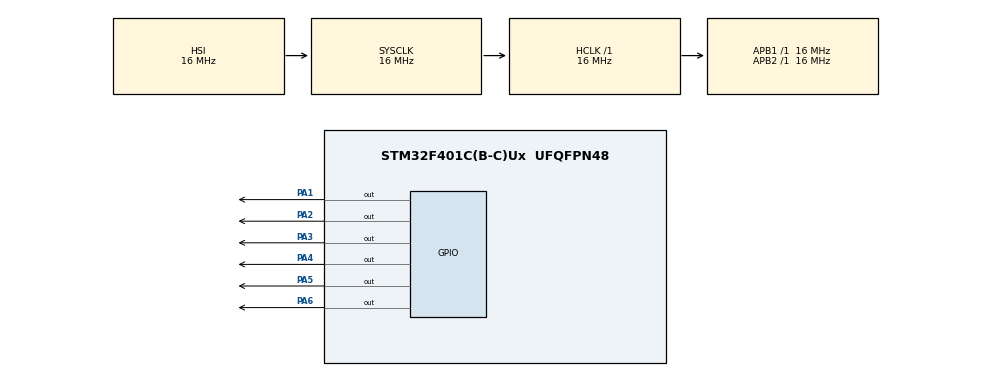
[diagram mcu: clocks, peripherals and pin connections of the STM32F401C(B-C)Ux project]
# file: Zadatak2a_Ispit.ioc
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FREERTOS.Tasks01=defaultTask,24,128,StartDefaultTask,Default,NULL,Dynamic,NULL,NULL
FREERTOS.configUSE_NEWLIB_REENTRANT=1
Mcu.Family=STM32F4
Mcu.Name=STM32F401C(B-C)Ux
Mcu.Package=UFQFPN48
NVIC.PriorityGroup=NVIC_PRIORITYGROUP_4
NVIC.TIM1_UP_TIM10_IRQn=true\:15\:0\:false\:false\:true\:false\:false\:true\:true
NVIC.TIM4_IRQn=true\:5\:0\:false\:false\:true\:true\:true\:true\:true
NVIC.TimeBase=TIM1_UP_TIM10_IRQn
NVIC.TimeBaseIP=TIM1
PA1.Signal=GPIO_Output
PA13.Mode=Serial_Wire
PA13.Signal=SYS_JTMS-SWDIO
PA14.Mode=Serial_Wire
PA14.Signal=SYS_JTCK-SWCLK
PA2.Signal=GPIO_Output
PA3.Signal=GPIO_Output
PA4.Signal=GPIO_Output
PA5.Signal=GPIO_Output
PA6.Signal=GPIO_Output
ProjectManager.HeapSize=0x200
ProjectManager.StackSize=0x400
ProjectManager.TargetToolchain=STM32CubeIDE
RCC.AHBFreq_Value=16000000
RCC.APB1Freq_Value=16000000
RCC.APB2Freq_Value=16000000
RCC.CortexFreq_Value=16000000
RCC.HSE_VALUE=25000000
RCC.HSI_VALUE=16000000
RCC.LSE_VALUE=32768
RCC.SYSCLKFreq_VALUE=16000000
RCC.VCOOutputFreq_Value=192000000
TIM4.Channel-Output\ Compare1\ No\ Output=TIM_CHANNEL_1
TIM4.Period=9999
TIM4.Prescaler=799
VP_FREERTOS_VS_CMSIS_V2.Mode=CMSIS_V2
VP_SYS_VS_tim1.Mode=TIM1
VP_TIM4_VS_no_output1.Mode=Output Compare1 No Output
board=custom

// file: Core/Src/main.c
/* USER CODE BEGIN Header */
/**
  ******************************************************************************
  * @file           : main.c
  * @brief          : Main program body
  ******************************************************************************
  * @attention
  *
  * Copyright (c) 2026 STMicroelectronics.
  * All rights reserved.
  *
  * This software is licensed under terms that can be found in the LICENSE file
  * in the root directory of this software component.
  * If no LICENSE file comes with this software, it is provided AS-IS.
  *
  ******************************************************************************
  */
/* USER CODE END Header */
#include "main.h"
#include "cmsis_os.h"

/* USER CODE BEGIN Includes */
#include "FreeRTOS.h"
#include "task.h"
#include "semphr.h"
#include "stm32f4xx_hal.h"

/* USER CODE END Includes */

TIM_HandleTypeDef htim4;

/* Definitions for defaultTask */
osThreadId_t defaultTaskHandle;
const osThreadAttr_t defaultTask_attributes = {
  .name = "defaultTask",
  .stack_size = 128 * 4,
  .priority = (osPriority_t) osPriorityNormal,
};
/* USER CODE BEGIN PV */
uint8_t stanje = 0;
/* USER CODE END PV */

void SystemClock_Config(void);
static void MX_GPIO_Init(void);
static void MX_TIM4_Init(void);
void StartDefaultTask(void *argument);

int main(void)
{

  /* MCU Configuration--------------------------------------------------------*/

  /* Reset of all peripherals, Initializes the Flash interface and the Systick. */
  HAL_Init();

  /* Configure the system clock */
  SystemClock_Config();

  /* Initialize all configured peripherals */
  MX_GPIO_Init();
  MX_TIM4_Init();
  /* USER CODE BEGIN 2 */

  HAL_TIM_Base_Start_IT(&htim4);

  /* USER CODE END 2 */

  /* Init scheduler */
  osKernelInitialize();

  /* Create the thread(s) */
  /* creation of defaultTask */
  defaultTaskHandle = osThreadNew(StartDefaultTask, NULL, &defaultTask_attributes);

  /* Start scheduler */
  osKernelStart();

  /* We should never get here as control is now taken by the scheduler */

  /* Infinite loop */
  while (1)
  {

  }
}

void SystemClock_Config(void)
{
  RCC_OscInitTypeDef RCC_OscInitStruct = {0};
  RCC_ClkInitTypeDef RCC_ClkInitStruct = {0};

  /** Configure the main internal regulator output voltage
  */
  __HAL_RCC_PWR_CLK_ENABLE();
  __HAL_PWR_VOLTAGESCALING_CONFIG(PWR_REGULATOR_VOLTAGE_SCALE2);

  /** Initializes the RCC Oscillators according to the specified parameters
  * in the RCC_OscInitTypeDef structure.
  */
  RCC_OscInitStruct.OscillatorType = RCC_OSCILLATORTYPE_HSI;
  RCC_OscInitStruct.HSIState = RCC_HSI_ON;
  RCC_OscInitStruct.HSICalibrationValue = RCC_HSICALIBRATION_DEFAULT;
  RCC_OscInitStruct.PLL.PLLState = RCC_PLL_NONE;
  if (HAL_RCC_OscConfig(&RCC_OscInitStruct) != HAL_OK)
  {
    Error_Handler();
  }

  /** Initializes the CPU, AHB and APB buses clocks
  */
  RCC_ClkInitStruct.ClockType = RCC_CLOCKTYPE_HCLK|RCC_CLOCKTYPE_SYSCLK
                              |RCC_CLOCKTYPE_PCLK1|RCC_CLOCKTYPE_PCLK2;
  RCC_ClkInitStruct.SYSCLKSource = RCC_SYSCLKSOURCE_HSI;
  RCC_ClkInitStruct.AHBCLKDivider = RCC_SYSCLK_DIV1;
  RCC_ClkInitStruct.APB1CLKDivider = RCC_HCLK_DIV1;
  RCC_ClkInitStruct.APB2CLKDivider = RCC_HCLK_DIV1;

  if (HAL_RCC_ClockConfig(&RCC_ClkInitStruct, FLASH_LATENCY_0) != HAL_OK)
  {
    Error_Handler();
  }
}

static void MX_TIM4_Init(void)
{

  TIM_MasterConfigTypeDef sMasterConfig = {0};
  TIM_OC_InitTypeDef sConfigOC = {0};

  htim4.Instance = TIM4;
  htim4.Init.Prescaler = 799;
  htim4.Init.CounterMode = TIM_COUNTERMODE_UP;
  htim4.Init.Period = 9999;
  htim4.Init.ClockDivision = TIM_CLOCKDIVISION_DIV1;
  htim4.Init.AutoReloadPreload = TIM_AUTORELOAD_PRELOAD_DISABLE;
  if (HAL_TIM_OC_Init(&htim4) != HAL_OK)
  {
    Error_Handler();
  }
  sMasterConfig.MasterOutputTrigger = TIM_TRGO_RESET;
  sMasterConfig.MasterSlaveMode = TIM_MASTERSLAVEMODE_DISABLE;
  if (HAL_TIMEx_MasterConfigSynchronization(&htim4, &sMasterConfig) != HAL_OK)
  {
    Error_Handler();
  }
  sConfigOC.OCMode = TIM_OCMODE_TIMING;
  sConfigOC.Pulse = 0;
  sConfigOC.OCPolarity = TIM_OCPOLARITY_HIGH;
  sConfigOC.OCFastMode = TIM_OCFAST_DISABLE;
  if (HAL_TIM_OC_ConfigChannel(&htim4, &sConfigOC, TIM_CHANNEL_1) != HAL_OK)
  {
    Error_Handler();
  }

}

static void MX_GPIO_Init(void)
{
  GPIO_InitTypeDef GPIO_InitStruct = {0};

  /* GPIO Ports Clock Enable */
  __HAL_RCC_GPIOA_CLK_ENABLE();

  /*Configure GPIO pin Output Level */
  HAL_GPIO_WritePin(GPIOA, GPIO_PIN_1|GPIO_PIN_2|GPIO_PIN_3|GPIO_PIN_4
                          |GPIO_PIN_5|GPIO_PIN_6, GPIO_PIN_RESET);

  /*Configure GPIO pins : PA1 PA2 PA3 PA4
                           PA5 PA6 */
  GPIO_InitStruct.Pin = GPIO_PIN_1|GPIO_PIN_2|GPIO_PIN_3|GPIO_PIN_4
                          |GPIO_PIN_5|GPIO_PIN_6;
  GPIO_InitStruct.Mode = GPIO_MODE_OUTPUT_PP;
  GPIO_InitStruct.Pull = GPIO_NOPULL;
  GPIO_InitStruct.Speed = GPIO_SPEED_FREQ_LOW;
  HAL_GPIO_Init(GPIOA, &GPIO_InitStruct);

}

void StartDefaultTask(void *argument)
{
  for(;;)
  {
    osDelay(1);
  }
}

void HAL_TIM_PeriodElapsedCallback(TIM_HandleTypeDef *htim)
{

  if (htim->Instance == TIM4)
  {
	  if (stanje == 0)
	  {
	    // PA2 – 500 ms
	    HAL_GPIO_TogglePin(GPIOA, GPIO_PIN_2);
	    HAL_GPIO_WritePin(GPIOA, GPIO_PIN_4, GPIO_PIN_RESET);

	    __HAL_TIM_SET_PRESCALER(&htim4, 3199);  // 200 ms
	    stanje = 1;
	   }
	   else
	   {
	    // PA4 – 200 ms
	    HAL_GPIO_TogglePin(GPIOA, GPIO_PIN_4);
	    HAL_GPIO_WritePin(GPIOA, GPIO_PIN_2, GPIO_PIN_RESET);

	    __HAL_TIM_SET_PRESCALER(&htim4, 799);   // 500 ms
	   stanje = 0;
	  }
	 __HAL_TIM_SET_COUNTER(&htim4, 0);
  }

}

void Error_Handler(void)
{
  __disable_irq();
  while (1)
  {
  }
}
